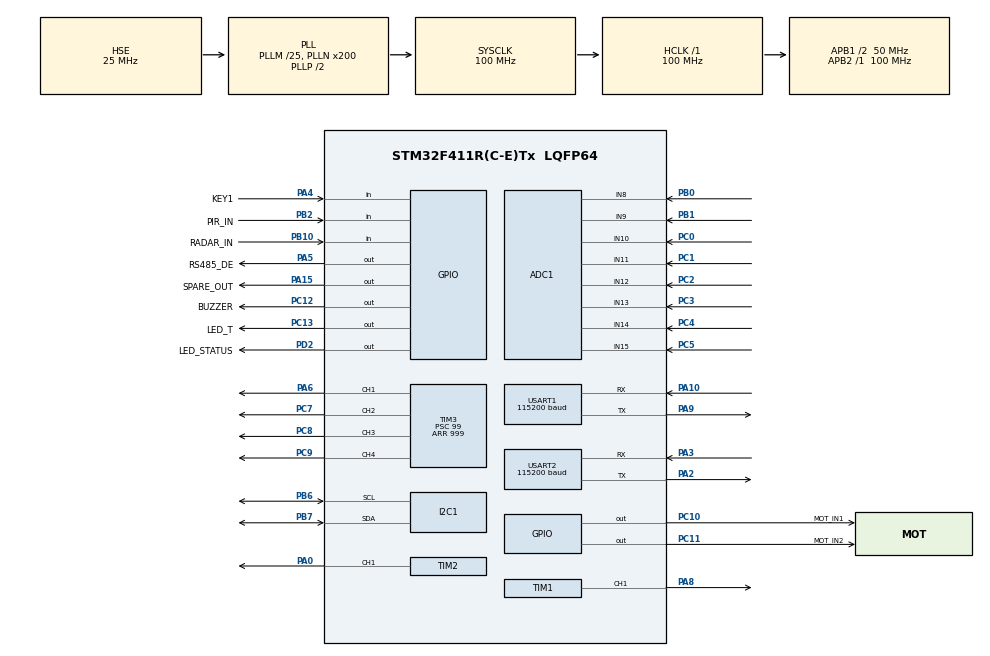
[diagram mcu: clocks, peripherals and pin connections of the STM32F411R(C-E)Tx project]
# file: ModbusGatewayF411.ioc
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ADC1.Channel-11\#ChannelRegularConversion=ADC_CHANNEL_8
ADC1.ContinuousConvMode=ENABLE
ADC1.DMAContinuousRequests=ENABLE
ADC1.NbrOfConversionFlag=1
ADC1.Rank-11\#ChannelRegularConversion=1
ADC1.SamplingTime-11\#ChannelRegularConversion=ADC_SAMPLETIME_3CYCLES
ADC1.ScanConvMode=ENABLE
ADC1.master=1
Dma.ADC1.0.Direction=DMA_PERIPH_TO_MEMORY
Dma.ADC1.0.FIFOMode=DMA_FIFOMODE_DISABLE
Dma.ADC1.0.Instance=DMA2_Stream0
Dma.ADC1.0.MemDataAlignment=DMA_MDATAALIGN_HALFWORD
Dma.ADC1.0.MemInc=DMA_MINC_ENABLE
Dma.ADC1.0.Mode=DMA_CIRCULAR
Dma.ADC1.0.PeriphDataAlignment=DMA_PDATAALIGN_HALFWORD
Dma.ADC1.0.PeriphInc=DMA_PINC_DISABLE
Dma.ADC1.0.Priority=DMA_PRIORITY_LOW
Dma.Request0=ADC1
FREERTOS.Tasks01=defaultTask,0,128,StartDefaultTask,Default,NULL,Dynamic,NULL,NULL
FREERTOS.configTOTAL_HEAP_SIZE=24576
I2C1.I2C_Mode=I2C_Fast
IWDG.Prescaler=IWDG_PRESCALER_64
IWDG.Reload=1000
Mcu.Family=STM32F4
Mcu.Name=STM32F411R(C-E)Tx
Mcu.Package=LQFP64
NVIC.DMA2_Stream0_IRQn=true\:5\:0\:false\:false\:true\:true\:false\:true\:true
NVIC.PriorityGroup=NVIC_PRIORITYGROUP_4
NVIC.TIM4_IRQn=true\:15\:0\:false\:false\:true\:false\:false\:true\:true
NVIC.TimeBase=TIM4_IRQn
NVIC.TimeBaseIP=TIM4
NVIC.USART2_IRQn=true\:5\:0\:false\:false\:true\:true\:true\:true\:true
PA0-WKUP.Signal=S_TIM2_CH1_ETR
PA10.Mode=Asynchronous
PA10.Signal=USART1_RX
PA15.GPIO_Label=SPARE_OUT
PA15.PinState=GPIO_PIN_RESET
PA15.Signal=GPIO_Output
PA2.Mode=Asynchronous
PA2.Signal=USART2_TX
PA3.Mode=Asynchronous
PA3.Signal=USART2_RX
PA4.GPIO_Label=KEY1
PA4.Signal=GPIO_Input
PA5.GPIO_Label=RS485_DE
PA5.PinState=GPIO_PIN_RESET
PA5.Signal=GPIO_Output
PA6.Signal=S_TIM3_CH1
PA8.Signal=S_TIM1_CH1
PA9.Mode=Asynchronous
PA9.Signal=USART1_TX
PB0.Signal=ADCx_IN8
PB1.Signal=ADCx_IN9
PB10.GPIO_Label=RADAR_IN
PB10.Signal=GPIO_Input
PB2.GPIO_Label=PIR_IN
PB2.Signal=GPIO_Input
PB6.Mode=I2C
PB6.Signal=I2C1_SCL
PB7.Mode=I2C
PB7.Signal=I2C1_SDA
PC0.Signal=ADCx_IN10
PC1.Signal=ADCx_IN11
PC10.GPIO_Label=MOT_IN1
PC10.PinState=GPIO_PIN_RESET
PC10.Signal=GPIO_Output
PC11.GPIO_Label=MOT_IN2
PC11.PinState=GPIO_PIN_RESET
PC11.Signal=GPIO_Output
PC12.GPIO_Label=BUZZER
PC12.PinState=GPIO_PIN_RESET
PC12.Signal=GPIO_Output
PC13-ANTI_TAMP.GPIO_Label=LED_T
PC13-ANTI_TAMP.PinState=GPIO_PIN_SET
PC13-ANTI_TAMP.Signal=GPIO_Output
PC14-OSC32_IN.Mode=LSE-External-Oscillator
PC14-OSC32_IN.Signal=RCC_OSC32_IN
PC15-OSC32_OUT.Mode=LSE-External-Oscillator
PC15-OSC32_OUT.Signal=RCC_OSC32_OUT
PC2.Signal=ADCx_IN12
PC3.Signal=ADCx_IN13
PC4.Signal=ADCx_IN14
PC5.Signal=ADCx_IN15
PC7.Signal=S_TIM3_CH2
PC8.Signal=S_TIM3_CH3
PC9.Signal=S_TIM3_CH4
PD2.GPIO_Label=LED_STATUS
PD2.PinState=GPIO_PIN_SET
PD2.Signal=GPIO_Output
PH0\ -\ OSC_IN.Mode=HSE-External-Oscillator
PH0\ -\ OSC_IN.Signal=RCC_OSC_IN
PH1\ -\ OSC_OUT.Mode=HSE-External-Oscillator
PH1\ -\ OSC_OUT.Signal=RCC_OSC_OUT
ProjectManager.HeapSize=0x200
ProjectManager.StackSize=0x400
ProjectManager.TargetToolchain=Makefile
RCC.48MHZClocksFreq_Value=50000000
RCC.AHBFreq_Value=100000000
RCC.APB1CLKDivider=RCC_HCLK_DIV2
RCC.APB1Freq_Value=50000000
RCC.APB1TimFreq_Value=100000000
RCC.APB2Freq_Value=100000000
RCC.APB2TimFreq_Value=100000000
RCC.CortexFreq_Value=100000000
RCC.HCLKFreq_Value=100000000
RCC.HSE_VALUE=25000000
RCC.HSI_VALUE=16000000
RCC.PLLM=25
RCC.PLLN=200
RCC.PLLP=RCC_PLLP_DIV2
RCC.PLLQ=4
RCC.PLLSourceVirtual=RCC_PLLSOURCE_HSE
RCC.SYSCLKFreq_VALUE=100000000
RCC.SYSCLKSource=RCC_SYSCLKSOURCE_PLLCLK
RCC.VCOOutputFreq_Value=200000000
SH.ADCx_IN10.0=ADC1_IN10,IN10
SH.ADCx_IN11.0=ADC1_IN11,IN11
SH.ADCx_IN12.0=ADC1_IN12,IN12
SH.ADCx_IN13.0=ADC1_IN13,IN13
SH.ADCx_IN14.0=ADC1_IN14,IN14
SH.ADCx_IN15.0=ADC1_IN15,IN15
SH.ADCx_IN8.0=ADC1_IN8,IN8
SH.ADCx_IN9.0=ADC1_IN9,IN9
SH.S_TIM1_CH1.0=TIM1_CH1,PWM Generation1 CH1
SH.S_TIM2_CH1_ETR.0=TIM2_CH1,PWM Generation1 CH1
SH.S_TIM3_CH1.0=TIM3_CH1,PWM Generation1 CH1
SH.S_TIM3_CH2.0=TIM3_CH2,PWM Generation2 CH2
SH.S_TIM3_CH3.0=TIM3_CH3,PWM Generation3 CH3
SH.S_TIM3_CH4.0=TIM3_CH4,PWM Generation4 CH4
TIM1.Channel-PWM\ Generation1\ CH1=TIM_CHANNEL_1
TIM1.Period=999
TIM1.Prescaler=99
TIM2.Channel-PWM\ Generation1\ CH1=TIM_CHANNEL_1
TIM2.Period=19999
TIM2.Prescaler=99
TIM3.Channel-PWM\ Generation1\ CH1=TIM_CHANNEL_1
TIM3.Channel-PWM\ Generation2\ CH2=TIM_CHANNEL_2
TIM3.Channel-PWM\ Generation3\ CH3=TIM_CHANNEL_3
TIM3.Channel-PWM\ Generation4\ CH4=TIM_CHANNEL_4
TIM3.Period=999
TIM3.Prescaler=99
USART1.BaudRate=115200
USART1.VirtualMode=VM_ASYNC
USART2.BaudRate=115200
USART2.VirtualMode=VM_ASYNC
VP_FREERTOS_VS_CMSIS_V1.Mode=CMSIS_V1
VP_IWDG_VS_IWDG.Mode=IWDG_Activate
VP_SYS_VS_tim4.Mode=TIM4
board=custom

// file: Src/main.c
/* USER CODE BEGIN Header */
/**
  ******************************************************************************
  * @file           : main.c
  * @brief          : Main program body
  ******************************************************************************
  * @attention
  *
  * Copyright (c) 2026 STMicroelectronics.
  * All rights reserved.
  *
  * This software is licensed under terms that can be found in the LICENSE file
  * in the root directory of this software component.
  * If no LICENSE file comes with this software, it is provided AS-IS.
  *
  ******************************************************************************
  */
/* USER CODE END Header */
#include "main.h"
#include "cmsis_os.h"
#include "adc.h"
#include "dma.h"
#include "i2c.h"
#include "iwdg.h"
#include "tim.h"
#include "usart.h"
#include "gpio.h"

/* USER CODE BEGIN Includes */
#include "app_main.h"   /* 本项目手写代码的入口（firmware-stm32/App） */
#include <stdio.h>      /* Error_Handler 里用 printf 把 HAL 初始化失败报出来 */
/* USER CODE END Includes */

void SystemClock_Config(void);
void MX_FREERTOS_Init(void);

int main(void)
{

  /* MCU Configuration--------------------------------------------------------*/

  /* Reset of all peripherals, Initializes the Flash interface and the Systick. */
  HAL_Init();

  /* Configure the system clock */
  SystemClock_Config();

  /* Initialize all configured peripherals */
  MX_GPIO_Init();
  MX_DMA_Init();
  MX_ADC1_Init();
  MX_I2C1_Init();
  MX_TIM1_Init();
  MX_TIM2_Init();
  MX_TIM3_Init();
  MX_USART1_UART_Init();
  MX_USART2_UART_Init();
  MX_IWDG_Init();
  /* USER CODE BEGIN 2 */

  /* 业务初始化：寄存器表、485 收发、ADC+DMA、PWM、传感器自检。
     必须在 MX_FREERTOS_Init() 之前——它要为随后的任务准备好队列与外设。 */
  app_init(&huart1, &huart2, &hadc1, &hi2c1, &htim1, &htim2, &htim3);

  /* USER CODE END 2 */

  /* Call init function for freertos objects (in cmsis_os2.c) */
  MX_FREERTOS_Init();

  /* Start scheduler */
  osKernelStart();

  /* We should never get here as control is now taken by the scheduler */

  /* Infinite loop */
  while (1)
  {

  }
}

void SystemClock_Config(void)
{
  RCC_OscInitTypeDef RCC_OscInitStruct = {0};
  RCC_ClkInitTypeDef RCC_ClkInitStruct = {0};

  /** Configure the main internal regulator output voltage
  */
  __HAL_RCC_PWR_CLK_ENABLE();
  __HAL_PWR_VOLTAGESCALING_CONFIG(PWR_REGULATOR_VOLTAGE_SCALE1);

  /** Initializes the RCC Oscillators according to the specified parameters
  * in the RCC_OscInitTypeDef structure.
  */
  RCC_OscInitStruct.OscillatorType = RCC_OSCILLATORTYPE_LSI|RCC_OSCILLATORTYPE_HSE;
  RCC_OscInitStruct.HSEState = RCC_HSE_ON;
  RCC_OscInitStruct.LSIState = RCC_LSI_ON;
  RCC_OscInitStruct.PLL.PLLState = RCC_PLL_ON;
  RCC_OscInitStruct.PLL.PLLSource = RCC_PLLSOURCE_HSE;
  RCC_OscInitStruct.PLL.PLLM = 25;
  RCC_OscInitStruct.PLL.PLLN = 200;
  RCC_OscInitStruct.PLL.PLLP = RCC_PLLP_DIV2;
  RCC_OscInitStruct.PLL.PLLQ = 4;   /* F4 HAL 的 PLLQ 是数字(2~15)，没有 RCC_PLLQ_DIVx 宏 */
  if (HAL_RCC_OscConfig(&RCC_OscInitStruct) != HAL_OK)
  {
    Error_Handler();
  }

  /** Initializes the CPU, AHB and APB buses clocks
  */
  RCC_ClkInitStruct.ClockType = RCC_CLOCKTYPE_HCLK|RCC_CLOCKTYPE_SYSCLK
                              |RCC_CLOCKTYPE_PCLK1|RCC_CLOCKTYPE_PCLK2;
  RCC_ClkInitStruct.SYSCLKSource = RCC_SYSCLKSOURCE_PLLCLK;
  RCC_ClkInitStruct.AHBCLKDivider = RCC_SYSCLK_DIV1;
  RCC_ClkInitStruct.APB1CLKDivider = RCC_HCLK_DIV2;
  RCC_ClkInitStruct.APB2CLKDivider = RCC_HCLK_DIV1;

  if (HAL_RCC_ClockConfig(&RCC_ClkInitStruct, FLASH_LATENCY_3) != HAL_OK)
  {
    Error_Handler();
  }
}

void HAL_TIM_PeriodElapsedCallback(TIM_HandleTypeDef *htim)
{
  if (htim->Instance == TIM4)
  {
    HAL_IncTick();
  }
}

void Error_Handler(void)
{
  /* USER CODE BEGIN Error_Handler_Debug */
  /* 让"某个 HAL 初始化失败"变成可见的错误信息，而不是静默死循环。
   * CubeMX 默认是 __disable_irq(); while(1); —— 什么都不说，
   * 表现就是"板子反复重启、串口只重复启动日志"，极难定位。 */
  printf("\r\n[FAULT] Error_Handler() 被调用：某个 HAL 初始化/操作失败了\r\n");
  HAL_IWDG_Refresh(&hiwdg);
  __disable_irq();
  while (1)
  {
  }
  /* USER CODE END Error_Handler_Debug */
}

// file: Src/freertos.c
/* USER CODE BEGIN Header */
/**
  ******************************************************************************
  * File Name          : freertos.c
  * Description        : Code for freertos applications
  ******************************************************************************
  * @attention
  *
  * Copyright (c) 2026 STMicroelectronics.
  * All rights reserved.
  *
  * This software is licensed under terms that can be found in the LICENSE file
  * in the root directory of this software component.
  * If no LICENSE file comes with this software, it is provided AS-IS.
  *
  ******************************************************************************
  */
/* USER CODE END Header */

#include "FreeRTOS.h"
#include "task.h"
#include "main.h"
#include "cmsis_os.h"

/* USER CODE BEGIN Includes */
#include "app_main.h"   /* app_start_tasks() 在这里声明 */
/* USER CODE END Includes */

osThreadId defaultTaskHandle;

void StartDefaultTask(void const * argument);

void MX_FREERTOS_Init(void); /* (MISRA C 2004 rule 8.1) */

/* GetIdleTaskMemory prototype (linked to static allocation support) */
void vApplicationGetIdleTaskMemory( StaticTask_t **ppxIdleTaskTCBBuffer, StackType_t **ppxIdleTaskStackBuffer, uint32_t *pulIdleTaskStackSize );

/* USER CODE BEGIN GET_IDLE_TASK_MEMORY */
static StaticTask_t xIdleTaskTCBBuffer;
static StackType_t xIdleStack[configMINIMAL_STACK_SIZE];

void vApplicationGetIdleTaskMemory( StaticTask_t **ppxIdleTaskTCBBuffer, StackType_t **ppxIdleTaskStackBuffer, uint32_t *pulIdleTaskStackSize )
{
  *ppxIdleTaskTCBBuffer = &xIdleTaskTCBBuffer;
  *ppxIdleTaskStackBuffer = &xIdleStack[0];
  *pulIdleTaskStackSize = configMINIMAL_STACK_SIZE;
  /* place for user code */
}
/* USER CODE END GET_IDLE_TASK_MEMORY */

void MX_FREERTOS_Init(void) {

  /* Create the thread(s) */
  /* definition and creation of defaultTask */
  osThreadDef(defaultTask, StartDefaultTask, osPriorityNormal, 0, 128);
  defaultTaskHandle = osThreadCreate(osThread(defaultTask), NULL);

  /* USER CODE BEGIN RTOS_THREADS */
  /* add threads, ... */
  /* 创建本项目的 6 个业务任务（栈大小与优先级见 CUBEMX-SETUP.md）
     用原生 xTaskCreate 而不是 CMSIS 包装，栈参数的单位是「字」。 */
  app_start_tasks();
  /* USER CODE END RTOS_THREADS */

}

void StartDefaultTask(void const * argument)
{
  for(;;)
  {
    osDelay(1);
  }
}
